# BL808 register map
File version: 0.1
Registers are access not given, no defined reset value unless marked. A register's access mark holds for its fields unless they carry their own. Offsets are from the block's base; [hi:lo] are bit positions; {n}, {i} and the like mark numbered series.

## DVP7
Base 0x30012700
Same registers: DVP0 0x30012000, DVP1 0x30012100, DVP3 0x30012300, DVP4 0x30012400, DVP5 0x30012500, DVP6 0x30012600
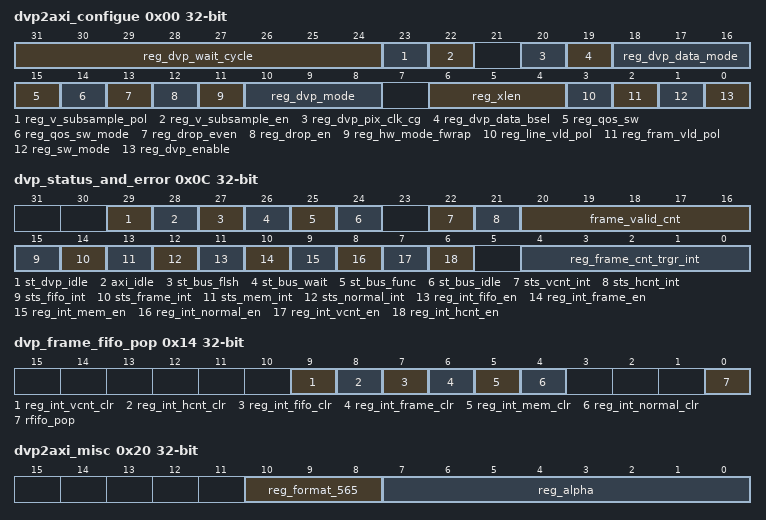
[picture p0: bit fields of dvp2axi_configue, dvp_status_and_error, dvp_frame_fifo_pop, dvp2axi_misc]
0x00 dvp2axi_configue
  [31:24] reg_dvp_wait_cycle rw — Cycles in FSM Wait mode
  [23] reg_v_subsample_pol rw — DVP2BUS vertical sub-sampling polarity 1'b0: Odd lines are masked 1'b1: Even lines are masked
  [22] reg_v_subsample_en rw — DVP2BUS vertical sub-sampling enable
  [20] reg_dvp_pix_clk_cg rw — DVP pix clk gate
  [19] reg_dvp_data_bsel rw — Byte select signal for DVP 8-bit mode, don't care if reg_dvp_data_8bit is disabled 1'b0: Select the lower byte of pix_data 1'b1: Select the upper byte of pix_data
  [18:16] reg_dvp_data_mode rw — DVP 8-bit mode enable 3'd0: DVP pix_data is 16-bit wide 3'd1: DVP pix_data is 24-bit mode 3'd2: DVP pix_data is 24-comp-16-bit mode 3'd3: DVP pix_data is 24-exp-32-bit mode 3'd4: DVP pix_data is 8-bit wide Others - Reserved
  [15] reg_qos_sw rw — AXI Qos software mode value
  [14] reg_qos_sw_mode rw — AXI QoS software mode enable
  [13] reg_drop_even rw — Only effect when reg_drop_en=1 : 1'b1 : Drop all even bytes 1'b0 : Drop all odd bytes
  [12] reg_drop_en rw — Drop mode Enable
  [11] reg_hw_mode_fwrap rw — DVP2BUS HW mode with frame start address wrap to reg_addr_start
  [10:8] reg_dvp_mode rw — Image senosr mode selection: 3'd0-Vsync&Hsync 3'd1-Vsync or Hsync 3'd2-Vsync 3'd3-Hsync
  [6:4] reg_xlen rw — burst length setting 3'd0 - Single / 3'd1 - INCR4 / 3'd2 - INCR8 3'd3 - INCR16 / 3'd5 - INCR32 / 3'd6 - INCR64
  [3] reg_line_vld_pol rw — Image sensor line valid polarity, 1'b0 - Activel low, 1'b1 - Active high
  [2] reg_fram_vld_pol rw — Image sensor frame valid polarity, 1'b0 - Activel low, 1'b1 - Active high
  [1] reg_sw_mode rw — DVP2BUS SW manual mode (don't care if reg_swap_mode is enabled)
  [0] reg_dvp_enable rw — module enable
0x04 dvp2axi_addr_start rw
  [31:0] reg_addr_start — AXI start address
0x08 dvp2axi_mem_bcnt rw
  [31:0] reg_mem_burst_cnt — AXI burst cnt before wrap to "reg_addr_start"
0x0C dvp_status_and_error
  [29] st_dvp_idle ro — DVP2BUS asynchronous fifo idle status
  [28] axi_idle ro — DVP2BUS AHB idle status
  [27] st_bus_flsh ro — DVP in flush state
  [26] st_bus_wait ro — DVP in wait state
  [25] st_bus_func ro — DVP in functional state
  [24] st_bus_idle ro — DVP in idle state
  [22] sts_vcnt_int ro — Vsync valid line count non-match interrupt status
  [21] sts_hcnt_int ro — Hsync valid pixel count non-match interrupt status
  [20:16] frame_valid_cnt ro — Frame counts in memory before read out in SW mode
  [15] sts_fifo_int ro — FIFO OverWrite interrupt status
  [14] sts_frame_int ro — Frame OverWrite interrupt status
  [13] sts_mem_int ro — Memory OverWrite interrupt status
  [12] sts_normal_int ro — Normal Write interrupt status
  [11] reg_int_fifo_en rw — FIFO OverWrite interrupt enable
  [10] reg_int_frame_en rw — Frame OverWrite interrupt enable
  [9] reg_int_mem_en rw — Memory OverWrite interrupt enable
  [8] reg_int_normal_en rw — Normal Write interrupt enable
  [7] reg_int_vcnt_en rw — Vsync valid line count match interrupt enable
  [6] reg_int_hcnt_en rw — Hsync valid pixel count match interrupt enable
  [4:0] reg_frame_cnt_trgr_int rw — Frame to issue interrupt at SW Mode
0x10 dvp2axi_frame_bcnt rw
  [31:0] reg_frame_byte_cnt — Single Frame byte cnt(Need pre-calculation)
0x14 dvp_frame_fifo_pop
  [9] reg_int_vcnt_clr write-once — Interrupt clear
  [8] reg_int_hcnt_clr write-once — Interrupt clear
  [7] reg_int_fifo_clr write-once — Interrupt clear
  [6] reg_int_frame_clr write-once — Interrupt clear
  [5] reg_int_mem_clr write-once — Interrupt clear
  [4] reg_int_normal_clr write-once — Interrupt clear
  [0] rfifo_pop write-once — Write this bit will trigger fifo pop
0x18 dvp2axi_frame_vld rw
  [31:0] reg_frame_n_vld — Bitwise frame valid in period
0x1C dvp2axi_frame_period
  [4:0] reg_frame_period rw — Frame period cnt. (EX. Set this register 0, the period is 1)
0x20 dvp2axi_misc
  [10:8] reg_format_565 rw — Only work when reg_dvp_data_mode=2 (24-comp-16-bit mode) 3'd0: B2(5)B1(6)B0(5) 3'd1: B1(5)B2(6)B0(5) 3'd2: B2(5)B0(6)B1(5) 3'd3: B0(5)B2(6)B1(5) 3'd4: B1(5)B0(6)B2(5) 3'd5: B0(5)B1(6)B2(5)
  [7:0] reg_alpha rw — Only work when "reg_dvp_data_mode==2'd3(DVP pix_data is 24-exp-32-bit mode)" The value of [31:24]
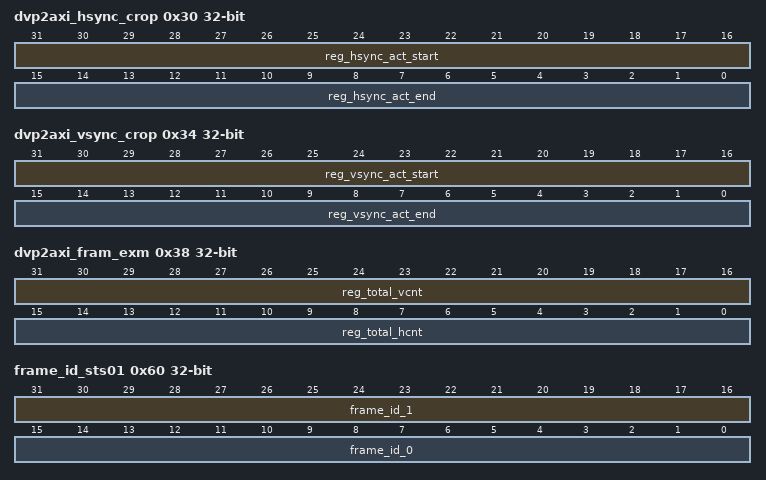
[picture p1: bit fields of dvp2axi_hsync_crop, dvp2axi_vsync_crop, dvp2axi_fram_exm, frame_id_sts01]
0x30 dvp2axi_hsync_crop rw
  [31:16] reg_hsync_act_start — Valid hsync start cnt
  [15:0] reg_hsync_act_end — Valid hsync end cnt
0x34 dvp2axi_vsync_crop rw
  [31:16] reg_vsync_act_start — Valid vsync start cnt
  [15:0] reg_vsync_act_end — Valid vsync end cnt
0x38 dvp2axi_fram_exm rw
  [31:16] reg_total_vcnt — Total valid line count in a frame
  [15:0] reg_total_hcnt — Total valid pix count in a line
{0x40+8i} frame_start_addr{i} ro (i=0..3)
  [31:0] frame_start_addr_{i} — DVP2BUS PIC {i} Start address
0x60 frame_id_sts01 ro
  [31:16] frame_id_1 — DVP2BUS PIC 1 ID
  [15:0] frame_id_0 — DVP2BUS PIC 0 ID
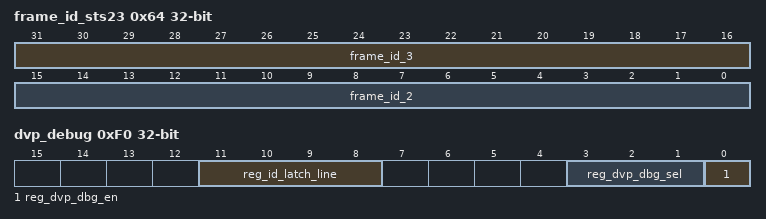
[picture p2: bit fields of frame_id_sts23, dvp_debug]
0x64 frame_id_sts23 ro
  [31:16] frame_id_3 — DVP2BUS PIC 3 ID
  [15:0] frame_id_2 — DVP2BUS PIC 2 ID
0xF0 dvp_debug
  [11:8] reg_id_latch_line rw — ID latch timing (line count)
  [3:1] reg_dvp_dbg_sel rw — DVP2BUS debgu flag selection
  [0] reg_dvp_dbg_en rw — DVP2BUS debgu flag enable
0xFC dvp_dummy_reg
